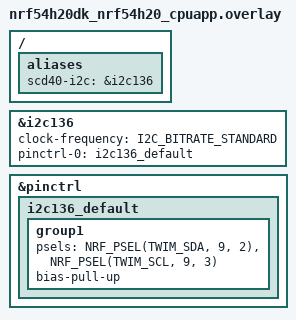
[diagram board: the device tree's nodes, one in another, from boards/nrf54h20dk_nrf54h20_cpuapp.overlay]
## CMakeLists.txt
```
cmake_minimum_required(VERSION 3.20.0)
find_package(Zephyr REQUIRED HINTS $ENV{ZEPHYR_BASE})

project(nrf54_coap_lwm2m_scd40
    VERSION 1.0.0
    DESCRIPTION "nRF54 CoAP/LWM2M air quality monitor using SCD40"
)

target_sources(app PRIVATE
    src/main.c
    src/scd40.c
)

target_include_directories(app PRIVATE src)
```

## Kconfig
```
mainmenu "nRF54 CoAP/LWM2M SCD40 Air Quality Monitor"

config APP_LWM2M_SERVER_URI
    string "LWM2M Server URI"
    default "coap://leshan.eclipseprojects.io:5683"
    help
      URI of the LWM2M server.
      Examples:
        coap://leshan.eclipseprojects.io:5683  (Leshan demo, no security)
        coap://192.168.1.100:5683              (local server)

config APP_LWM2M_ENDPOINT_NAME
    string "LWM2M Endpoint Name"
    default "nrf54-scd40-001"
    help
      LWM2M endpoint name used for device registration.

config APP_SENSOR_READ_INTERVAL_SEC
    int "Sensor read interval (seconds)"
    default 30
    range 5 3600
    help
      How often to read the SCD40 and update LWM2M object values.

source "Kconfig.zephyr"
```

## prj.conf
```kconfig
# ─── Kernel ───────────────────────────────────────────────────────────────────
CONFIG_MAIN_STACK_SIZE=4096
CONFIG_HEAP_MEM_POOL_SIZE=16384

# ─── Logging ──────────────────────────────────────────────────────────────────
CONFIG_LOG=y
CONFIG_LOG_DEFAULT_LEVEL=3
CONFIG_CBPRINTF_FP_SUPPORT=y

# ─── I2C (for SCD40) ──────────────────────────────────────────────────────────
CONFIG_I2C=y

# ─── Networking ───────────────────────────────────────────────────────────────
CONFIG_NETWORKING=y
CONFIG_NET_IPV4=y
CONFIG_NET_IPV6=y
CONFIG_NET_UDP=y
CONFIG_NET_SOCKETS=y
CONFIG_NET_SOCKETS_POSIX_NAMES=y

# Auto-configure networking (DHCP for Ethernet, etc.)
CONFIG_NET_CONFIG_SETTINGS=y
CONFIG_NET_CONFIG_AUTO_INIT=y
CONFIG_NET_CONFIG_NEED_IPV4=y
CONFIG_NET_DHCPV4=y

# ─── CoAP ─────────────────────────────────────────────────────────────────────
CONFIG_COAP=y

# ─── LWM2M ────────────────────────────────────────────────────────────────────
CONFIG_LWM2M=y
CONFIG_LWM2M_ENGINE_MAX_MESSAGES=20
CONFIG_LWM2M_ENGINE_MAX_PENDING=10
CONFIG_LWM2M_ENGINE_MAX_REPLIES=10
CONFIG_LWM2M_COAP_BLOCK_SIZE=512
CONFIG_LWM2M_ENGINE_DEFAULT_LIFETIME=120
CONFIG_LWM2M_RD_CLIENT_SUPPORT=y
CONFIG_LWM2M_RD_CLIENT_SUPPORT_BOOTSTRAP=n
CONFIG_LWM2M_LOG_LEVEL_INF=y

# LWM2M Device object (Object 3) metadata
CONFIG_LWM2M_DEVICE_MANUFACTURER="Nordic/Sensirion"
CONFIG_LWM2M_DEVICE_MODEL_NUMBER="nRF54-SCD40"
CONFIG_LWM2M_DEVICE_SERIAL_NUMBER="SCD40-001"
CONFIG_LWM2M_DEVICE_FIRMWARE_VERSION="1.0.0"
CONFIG_LWM2M_DEVICE_TYPE="AirQualityMonitor"
CONFIG_LWM2M_DEVICE_HARDWARE_VERSION="1.0"
CONFIG_LWM2M_DEVICE_SOFTWARE_VERSION="1.0.0"

# IPSO sensor objects
CONFIG_LWM2M_IPSO_SUPPORT=y
CONFIG_LWM2M_IPSO_TEMP_SENSOR=y       # Object 3303 - Temperature
CONFIG_LWM2M_IPSO_HUMIDITY_SENSOR=y   # Object 3304 - Humidity
CONFIG_LWM2M_IPSO_GENERIC_SENSOR=y    # Object 3300 - Generic (CO2 in ppm)

# ─── DNS ──────────────────────────────────────────────────────────────────────
CONFIG_DNS_RESOLVER=y
CONFIG_DNS_SERVER_IP_ADDRESSES=y
CONFIG_NET_HOSTNAME_ENABLE=y
CONFIG_NET_HOSTNAME="nrf54-scd40"

# ─── Misc ─────────────────────────────────────────────────────────────────────
CONFIG_REBOOT=y
CONFIG_POSIX_API=y
CONFIG_NET_MGMT=y
CONFIG_NET_MGMT_EVENT=y
CONFIG_NET_MGMT_EVENT_STACK_SIZE=1024
CONFIG_SYSTEM_WORKQUEUE_STACK_SIZE=2048
```

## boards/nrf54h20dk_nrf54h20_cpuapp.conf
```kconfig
# nRF54H20DK - Application core
#
# nRF54H20 does not have an integrated LTE modem.
# Connectivity options:
#   - nRF9160 as LTE modem companion (via UART AT commands)
#   - nRF7002 Wi-Fi companion chip
#   - Ethernet via external PHY
#
# For nRF9160 LTE companion (recommended for WAN):
# CONFIG_LTE_LINK_CONTROL=y
# CONFIG_MODEM_MODULES=y

CONFIG_ENTROPY_NRF5_RNG=y
```

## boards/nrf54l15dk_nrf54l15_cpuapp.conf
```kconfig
# nRF54L15DK - Application core
#
# nRF54L15 does not have an integrated LTE modem or Ethernet.
# Connectivity options:
#   - OpenThread (IEEE 802.15.4) via a Thread border router
#   - Wi-Fi via nRF7002 companion chip
#   - USB CDC-ECM for development/testing
#
# Uncomment the relevant transport below.

# ── Option A: OpenThread (recommended for production) ──────────────────────────
# CONFIG_OPENTHREAD=y
# CONFIG_OPENTHREAD_MTD=y
# CONFIG_OPENTHREAD_MANUAL_START=n
# CONFIG_NET_L2_OPENTHREAD=y
# CONFIG_OPENTHREAD_CHANNEL=15
# CONFIG_OPENTHREAD_PANID=0xabcd
# CONFIG_OPENTHREAD_NETWORK_NAME="SCD40Net"
# CONFIG_OPENTHREAD_MASTERKEY="00112233445566778899aabbccddeeff"

# ── Option B: USB CDC-ECM (development/PC tethering) ──────────────────────────
# CONFIG_USB_DEVICE_STACK=y
# CONFIG_USB_CDC_ECM=y
# CONFIG_NET_L2_ETHERNET=y

# ── Common for nRF54L15 ────────────────────────────────────────────────────────
CONFIG_ENTROPY_NRF5_RNG=y
```

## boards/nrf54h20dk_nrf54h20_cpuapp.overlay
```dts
/*
 * SCD40 I2C overlay for nRF54H20DK (Application core)
 *
 * IMPORTANT: Verify the pin assignments match your hardware connections!
 * Check nRF54H20DK schematic for the Arduino header I2C pin mapping.
 *
 * Default below uses TWIM136:
 *   SDA -> P9.02   (Arduino A4)
 *   SCL -> P9.03   (Arduino A5)
 *
 * SCD40 wiring:
 *   SCD40 VDD  -> 3.3V
 *   SCD40 GND  -> GND
 *   SCD40 SDA  -> SDA pin (+ 4.7kΩ pull-up to 3.3V)
 *   SCD40 SCL  -> SCL pin (+ 4.7kΩ pull-up to 3.3V)
 *   SCD40 SEL  -> GND      (selects I2C mode)
 */

/ {
    aliases {
        scd40-i2c = &i2c136;
    };
};

&i2c136 {
    status = "okay";
    clock-frequency = <I2C_BITRATE_STANDARD>; /* 100 kHz */
    pinctrl-0 = <&i2c136_default>;
    pinctrl-names = "default";
};

&pinctrl {
    i2c136_default: i2c136_default {
        group1 {
            psels = <NRF_PSEL(TWIM_SDA, 9, 2)>,
                    <NRF_PSEL(TWIM_SCL, 9, 3)>;
            bias-pull-up;
        };
    };
};
```

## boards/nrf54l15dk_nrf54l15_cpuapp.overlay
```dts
/*
 * SCD40 I2C overlay for nRF54L15DK (Application core)
 *
 * IMPORTANT: Verify the pin assignments match your hardware connections!
 * Check nRF54L15DK schematic for the Arduino header I2C pin mapping.
 *
 * Default below uses TWIM20:
 *   SDA -> P1.11   (Arduino A4)
 *   SCL -> P1.12   (Arduino A5)
 *
 * SCD40 wiring:
 *   SCD40 VDD  -> 3.3V
 *   SCD40 GND  -> GND
 *   SCD40 SDA  -> P1.11 (+ 4.7kΩ pull-up to 3.3V)
 *   SCD40 SCL  -> P1.12 (+ 4.7kΩ pull-up to 3.3V)
 *   SCD40 SEL  -> GND   (selects I2C mode)
 */

/ {
    aliases {
        scd40-i2c = &i2c20;
    };
};

&i2c20 {
    status = "okay";
    clock-frequency = <I2C_BITRATE_STANDARD>; /* 100 kHz */
    pinctrl-0 = <&i2c20_default>;
    pinctrl-names = "default";
};

&pinctrl {
    i2c20_default: i2c20_default {
        group1 {
            psels = <NRF_PSEL(TWIM_SDA, 1, 11)>,
                    <NRF_PSEL(TWIM_SCL, 1, 12)>;
            bias-pull-up;
        };
    };
};
```

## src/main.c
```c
/*
 * nRF54 CoAP/LWM2M Air Quality Monitor
 *
 * Reads CO2, temperature, and relative humidity from a Sensirion SCD40
 * sensor via I2C and publishes the values to an LWM2M server over CoAP/UDP.
 *
 * LWM2M object mapping:
 *   3303/0  – Temperature        (°C)
 *   3304/0  – Humidity           (%RH)
 *   3300/0  – Generic Sensor     (CO2, ppm)
 *
 * Build targets:
 *   west build -b nrf54l15dk/nrf54l15/cpuapp
 *   west build -b nrf54h20dk/nrf54h20/cpuapp
 */

#include <zephyr/kernel.h>
#include <zephyr/device.h>
#include <zephyr/drivers/i2c.h>
#include <zephyr/logging/log.h>
#include <zephyr/net/net_if.h>
#include <zephyr/net/net_mgmt.h>
#include <zephyr/net/net_event.h>
#include <zephyr/net/lwm2m.h>

#include "scd40.h"

LOG_MODULE_REGISTER(main, LOG_LEVEL_INF);

/* ── I2C device (alias defined in board overlay) ────────────────────────── */
#define I2C_NODE DT_ALIAS(scd40_i2c)
BUILD_ASSERT(DT_NODE_HAS_STATUS(I2C_NODE, okay),
             "scd40-i2c alias not enabled. Check your board overlay.");

static const struct device *i2c_dev = DEVICE_DT_GET(I2C_NODE);

/* ── Network ready synchronisation ─────────────────────────────────────── */
static K_SEM_DEFINE(net_ready_sem, 0, 1);
static struct net_mgmt_event_callback net_mgmt_cb;

static void on_net_event(struct net_mgmt_event_callback *cb,
                         uint32_t event, struct net_if *iface)
{
    ARG_UNUSED(cb);
    ARG_UNUSED(iface);

    if (event == NET_EVENT_IPV4_ADDR_ADD) {
        LOG_INF("Network: IPv4 address obtained");
        k_sem_give(&net_ready_sem);
    } else if (event == NET_EVENT_IPV6_ADDR_ADD) {
        LOG_INF("Network: IPv6 address obtained");
        k_sem_give(&net_ready_sem);
    }
}

/* ── LWM2M client context ───────────────────────────────────────────────── */
static struct lwm2m_ctx lwm2m_client;

static void lwm2m_event_handler(struct lwm2m_ctx *client,
                                enum lwm2m_rd_client_event event)
{
    ARG_UNUSED(client);

    switch (event) {
    case LWM2M_RD_CLIENT_EVENT_REGISTRATION_COMPLETE:
        LOG_INF("LWM2M: registered with server");
        break;
    case LWM2M_RD_CLIENT_EVENT_REG_UPDATE_COMPLETE:
        LOG_INF("LWM2M: registration updated");
        break;
    case LWM2M_RD_CLIENT_EVENT_REGISTRATION_FAILURE:
        LOG_ERR("LWM2M: registration failed");
        break;
    case LWM2M_RD_CLIENT_EVENT_DEREGISTER_FAILURE:
        LOG_ERR("LWM2M: deregistration failed");
        break;
    case LWM2M_RD_CLIENT_EVENT_DISCONNECT:
        LOG_WRN("LWM2M: disconnected");
        break;
    case LWM2M_RD_CLIENT_EVENT_BOOTSTRAP_REG_FAILURE:
        LOG_ERR("LWM2M: bootstrap registration failed");
        break;
    case LWM2M_RD_CLIENT_EVENT_BOOTSTRAP_REG_COMPLETE:
        LOG_INF("LWM2M: bootstrap complete");
        break;
    default:
        break;
    }
}

/* ── LWM2M setup ────────────────────────────────────────────────────────── */
static int lwm2m_setup(void)
{
    int ret;

    /* ── Security object (Object 0, instance 0) ───────────────────────── */
    /* Server URI */
    ret = lwm2m_engine_set_string("0/0/0", CONFIG_APP_LWM2M_SERVER_URI);
    if (ret < 0) {
        LOG_ERR("Failed to set server URI: %d", ret);
        return ret;
    }
    /* Not a bootstrap server */
    ret = lwm2m_engine_set_bool("0/0/1", false);
    if (ret < 0) {
        return ret;
    }
    /* Security mode: NoSec (3) */
    ret = lwm2m_engine_set_u8("0/0/2", 3U);
    if (ret < 0) {
        return ret;
    }
    /* Short Server ID */
    ret = lwm2m_engine_set_u16("0/0/10", 1U);
    if (ret < 0) {
        return ret;
    }

    /* ── Server object (Object 1, instance 0) ─────────────────────────── */
    ret = lwm2m_engine_set_u16("1/0/0", 1U);   /* Short Server ID */
    if (ret < 0) {
        return ret;
    }
    ret = lwm2m_engine_set_u32("1/0/1",         /* Lifetime (s) */
                               CONFIG_LWM2M_ENGINE_DEFAULT_LIFETIME);
    if (ret < 0) {
        return ret;
    }
    ret = lwm2m_engine_set_u8("1/0/6", 0U);    /* Notification storing off */
    if (ret < 0) {
        return ret;
    }
    ret = lwm2m_engine_set_string("1/0/7", "U"); /* UDP binding */
    if (ret < 0) {
        return ret;
    }

    /* ── IPSO Temperature sensor (Object 3303, instance 0) ───────────── */
    ret = lwm2m_engine_create_obj_inst("3303/0");
    if (ret < 0 && ret != -EEXIST) {
        LOG_ERR("Failed to create 3303/0: %d", ret);
        return ret;
    }
    lwm2m_engine_set_string("3303/0/5701", "Cel"); /* Units */

    /* ── IPSO Humidity sensor (Object 3304, instance 0) ──────────────── */
    ret = lwm2m_engine_create_obj_inst("3304/0");
    if (ret < 0 && ret != -EEXIST) {
        LOG_ERR("Failed to create 3304/0: %d", ret);
        return ret;
    }
    lwm2m_engine_set_string("3304/0/5701", "%RH"); /* Units */

    /* ── IPSO Generic sensor (Object 3300, instance 0) – CO2 ─────────── */
    ret = lwm2m_engine_create_obj_inst("3300/0");
    if (ret < 0 && ret != -EEXIST) {
        LOG_ERR("Failed to create 3300/0: %d", ret);
        return ret;
    }
    lwm2m_engine_set_string("3300/0/5701", "ppm"); /* Units */

    LOG_INF("LWM2M objects created: 3303/0 (temp), 3304/0 (hum), 3300/0 (CO2)");
    return 0;
}

/* ── Push current sensor data into LWM2M resources ─────────────────────── */
static void update_lwm2m_values(const struct scd40_data *d)
{
    double temp = d->temperature;
    double hum  = d->humidity;
    double co2  = (double)d->co2_ppm;

    lwm2m_engine_set_float("3303/0/5700", &temp);
    lwm2m_engine_set_float("3304/0/5700", &hum);
    lwm2m_engine_set_float("3300/0/5700", &co2);

    LOG_INF("LWM2M updated → CO2=%u ppm  Temp=%.1f C  Hum=%.1f %%RH",
            d->co2_ppm, d->temperature, d->humidity);
}

/* ── Main ───────────────────────────────────────────────────────────────── */
int main(void)
{
    int ret;
    struct scd40_data sensor;

    LOG_INF("=== nRF54 CoAP/LWM2M SCD40 Air Quality Monitor ===");
    LOG_INF("Endpoint: %s", CONFIG_APP_LWM2M_ENDPOINT_NAME);
    LOG_INF("Server:   %s", CONFIG_APP_LWM2M_SERVER_URI);

    /* ── 1. Initialise SCD40 ─────────────────────────────────────────── */
    ret = scd40_init(i2c_dev);
    if (ret < 0) {
        LOG_ERR("SCD40 init failed (%d). Check I2C wiring.", ret);
        return ret;
    }

    ret = scd40_start_periodic_measurement(i2c_dev);
    if (ret < 0) {
        LOG_ERR("SCD40 start measurement failed: %d", ret);
        return ret;
    }

    /* SCD40 needs at least 5 s to produce the first valid measurement */
    LOG_INF("Waiting 5 s for first SCD40 measurement...");
    k_sleep(K_SECONDS(5));

    /* ── 2. Wait for IP connectivity ─────────────────────────────────── */
    net_mgmt_init_event_callback(&net_mgmt_cb, on_net_event,
                                 NET_EVENT_IPV4_ADDR_ADD |
                                 NET_EVENT_IPV6_ADDR_ADD);
    net_mgmt_add_event_callback(&net_mgmt_cb);

    /* If an address was already assigned before we registered the callback,
     * the semaphore would never be given. Check now and skip the wait. */
    struct net_if *iface = net_if_get_default();

    if (iface && net_if_flag_is_set(iface, NET_IF_DORMANT)) {
        LOG_INF("Network: waiting for link...");
    } else {
        k_sem_give(&net_ready_sem); /* already up */
    }

    LOG_INF("Network: waiting for IP address (timeout 60 s)...");
    ret = k_sem_take(&net_ready_sem, K_SECONDS(60));
    if (ret < 0) {
        LOG_ERR("Network: timed out waiting for IP address");
        return ret;
    }

    /* Short delay to let DHCP/SLAAC settle */
    k_sleep(K_SECONDS(2));

    /* ── 3. Setup LWM2M objects ──────────────────────────────────────── */
    ret = lwm2m_setup();
    if (ret < 0) {
        LOG_ERR("LWM2M setup failed: %d", ret);
        return ret;
    }

    /* ── 4. Start LWM2M RD client ────────────────────────────────────── */
    memset(&lwm2m_client, 0, sizeof(lwm2m_client));
    lwm2m_client.sock_fd = -1;

    ret = lwm2m_rd_client_start(&lwm2m_client,
                                CONFIG_APP_LWM2M_ENDPOINT_NAME,
                                0,                    /* flags */
                                lwm2m_event_handler,
                                NULL);                /* observe_cb */
    if (ret < 0) {
        LOG_ERR("LWM2M RD client start failed: %d", ret);
        return ret;
    }

    /* ── 5. Periodic sensor read & LWM2M update loop ─────────────────── */
    LOG_INF("Entering sensor loop (interval: %d s)",
            CONFIG_APP_SENSOR_READ_INTERVAL_SEC);

    while (true) {
        k_sleep(K_SECONDS(CONFIG_APP_SENSOR_READ_INTERVAL_SEC));

        ret = scd40_read_measurement(i2c_dev, &sensor);
        if (ret == -EAGAIN) {
            LOG_WRN("SCD40 data not ready yet, retrying next cycle");
            continue;
        }
        if (ret < 0) {
            LOG_ERR("SCD40 read error: %d", ret);
            continue;
        }

        update_lwm2m_values(&sensor);
    }

    /* unreachable */
    return 0;
}
```

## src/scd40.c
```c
#include <zephyr/kernel.h>
#include <zephyr/drivers/i2c.h>
#include <zephyr/logging/log.h>

#include "scd40.h"

LOG_MODULE_REGISTER(scd40, LOG_LEVEL_INF);

/* ── SCD40 command opcodes ───────────────────────────────────────────────── */
#define CMD_START_PERIODIC_MEAS     0x21B1U
#define CMD_READ_MEASUREMENT        0xEC05U
#define CMD_STOP_PERIODIC_MEAS      0x3F86U
#define CMD_GET_DATA_READY_STATUS   0xE4B8U
#define CMD_REINIT                  0x3646U
#define CMD_SOFT_RESET              0xD304U

/* ── Timing (ms) ─────────────────────────────────────────────────────────── */
#define DELAY_STOP_MEAS_MS      500
#define DELAY_REINIT_MS          20
#define DELAY_CMD_RESPONSE_MS     1

/* ── Sensirion CRC-8 (poly 0x31, init 0xFF) ─────────────────────────────── */
static uint8_t crc8(const uint8_t *data, size_t len)
{
    uint8_t crc = 0xFFU;

    for (size_t i = 0; i < len; i++) {
        crc ^= data[i];
        for (int b = 0; b < 8; b++) {
            crc = (crc & 0x80U) ? ((crc << 1) ^ 0x31U) : (crc << 1);
        }
    }
    return crc;
}

/* ── Low-level helpers ───────────────────────────────────────────────────── */

static int send_cmd(const struct device *dev, uint16_t cmd)
{
    uint8_t buf[2] = {(uint8_t)(cmd >> 8), (uint8_t)(cmd & 0xFFU)};

    return i2c_write(dev, buf, sizeof(buf), SCD40_I2C_ADDR);
}

/**
 * Read @p num_words 16-bit words (each followed by a CRC byte) from the
 * sensor.  The caller supplies a buffer of at least num_words * 3 bytes.
 * Returns -EIO on CRC mismatch.
 */
static int read_words(const struct device *dev, uint8_t *buf, size_t num_words)
{
    int ret = i2c_read(dev, buf, num_words * 3U, SCD40_I2C_ADDR);

    if (ret < 0) {
        return ret;
    }

    for (size_t i = 0; i < num_words; i++) {
        uint8_t *w = &buf[i * 3U];

        if (crc8(w, 2U) != w[2]) {
            LOG_ERR("CRC error on word %zu (got 0x%02X, expected 0x%02X)",
                    i, w[2], crc8(w, 2U));
            return -EIO;
        }
    }
    return 0;
}

/* ── Public API ──────────────────────────────────────────────────────────── */

int scd40_init(const struct device *i2c_dev)
{
    if (!device_is_ready(i2c_dev)) {
        LOG_ERR("I2C device '%s' is not ready", i2c_dev->name);
        return -ENODEV;
    }

    /* Stop any measurement that may still be running (ignore errors here:
     * the sensor may not have been started yet on a cold boot). */
    (void)send_cmd(i2c_dev, CMD_STOP_PERIODIC_MEAS);
    k_sleep(K_MSEC(DELAY_STOP_MEAS_MS));

    /* Reinitialise NVM-loaded calibration values */
    int ret = send_cmd(i2c_dev, CMD_REINIT);

    if (ret < 0) {
        LOG_ERR("REINIT command failed: %d", ret);
        return ret;
    }
    k_sleep(K_MSEC(DELAY_REINIT_MS));

    LOG_INF("SCD40 initialised on %s", i2c_dev->name);
    return 0;
}

int scd40_start_periodic_measurement(const struct device *i2c_dev)
{
    int ret = send_cmd(i2c_dev, CMD_START_PERIODIC_MEAS);

    if (ret < 0) {
        LOG_ERR("START_PERIODIC_MEASUREMENT failed: %d", ret);
        return ret;
    }
    LOG_INF("SCD40 periodic measurement started (5 s interval)");
    return 0;
}

int scd40_stop_periodic_measurement(const struct device *i2c_dev)
{
    int ret = send_cmd(i2c_dev, CMD_STOP_PERIODIC_MEAS);

    if (ret < 0) {
        return ret;
    }
    k_sleep(K_MSEC(DELAY_STOP_MEAS_MS));
    return 0;
}

int scd40_get_data_ready(const struct device *i2c_dev, bool *ready)
{
    int ret = send_cmd(i2c_dev, CMD_GET_DATA_READY_STATUS);

    if (ret < 0) {
        return ret;
    }
    k_sleep(K_MSEC(DELAY_CMD_RESPONSE_MS));

    uint8_t buf[3];

    ret = i2c_read(i2c_dev, buf, sizeof(buf), SCD40_I2C_ADDR);
    if (ret < 0) {
        return ret;
    }
    if (crc8(buf, 2U) != buf[2]) {
        LOG_ERR("CRC error reading data-ready status");
        return -EIO;
    }

    /* Bits [10:0] non-zero means a fresh sample is available */
    uint16_t status = ((uint16_t)buf[0] << 8) | buf[1];

    *ready = (status & 0x07FFU) != 0U;
    return 0;
}

int scd40_read_measurement(const struct device *i2c_dev,
                           struct scd40_data *data)
{
    bool ready = false;
    int  ret   = scd40_get_data_ready(i2c_dev, &ready);

    if (ret < 0) {
        LOG_ERR("Failed to check data-ready: %d", ret);
        return ret;
    }
    if (!ready) {
        return -EAGAIN;
    }

    ret = send_cmd(i2c_dev, CMD_READ_MEASUREMENT);
    if (ret < 0) {
        LOG_ERR("READ_MEASUREMENT command failed: %d", ret);
        return ret;
    }
    k_sleep(K_MSEC(DELAY_CMD_RESPONSE_MS));

    /* Response: [CO2_H, CO2_L, CRC, TEMP_H, TEMP_L, CRC, RH_H, RH_L, CRC] */
    uint8_t buf[9];

    ret = read_words(i2c_dev, buf, 3U);
    if (ret < 0) {
        LOG_ERR("Failed to read measurement data: %d", ret);
        return ret;
    }

    uint16_t raw_co2  = ((uint16_t)buf[0] << 8) | buf[1];
    uint16_t raw_temp = ((uint16_t)buf[3] << 8) | buf[4];
    uint16_t raw_rh   = ((uint16_t)buf[6] << 8) | buf[7];

    data->co2_ppm    = raw_co2;
    data->temperature = -45.0 + 175.0 * (double)raw_temp / 65535.0;
    data->humidity    = 100.0 * (double)raw_rh   / 65535.0;

    LOG_INF("SCD40: CO2=%u ppm  Temp=%.2f C  Hum=%.2f %%RH",
            data->co2_ppm, data->temperature, data->humidity);
    return 0;
}
```

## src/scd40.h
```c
#ifndef SCD40_H_
#define SCD40_H_

#include <stdint.h>
#include <stdbool.h>
#include <zephyr/device.h>

/** SCD40 I2C 7-bit address */
#define SCD40_I2C_ADDR  0x62U

/**
 * Measurement data from a single SCD40 reading.
 * Populated by scd40_read_measurement().
 */
struct scd40_data {
    uint16_t co2_ppm;    /* CO2 concentration [ppm] */
    double   temperature; /* Temperature [°C] */
    double   humidity;    /* Relative humidity [%RH] */
};

/**
 * @brief  Stop any ongoing measurement, reinitialise the sensor.
 * @return 0 on success, negative errno on I2C error.
 */
int scd40_init(const struct device *i2c_dev);

/**
 * @brief  Start periodic measurements (one sample every ~5 s).
 * @return 0 on success, negative errno on I2C error.
 */
int scd40_start_periodic_measurement(const struct device *i2c_dev);

/**
 * @brief  Stop periodic measurements.
 *         Required before issuing single-shot commands or reconfiguring.
 * @return 0 on success, negative errno on I2C error.
 */
int scd40_stop_periodic_measurement(const struct device *i2c_dev);

/**
 * @brief  Check whether a fresh measurement is available.
 * @param  ready  Set to true when new data is ready to read.
 * @return 0 on success, negative errno on I2C / CRC error.
 */
int scd40_get_data_ready(const struct device *i2c_dev, bool *ready);

/**
 * @brief  Read the latest CO2, temperature, and humidity values.
 *         Checks data-ready status internally; returns -EAGAIN if
 *         the sensor has no fresh sample yet.
 * @param  data   Output struct filled with measurement values.
 * @return 0 on success, -EAGAIN if data not ready, negative errno on error.
 */
int scd40_read_measurement(const struct device *i2c_dev,
                           struct scd40_data *data);

#endif /* SCD40_H_ */
```
